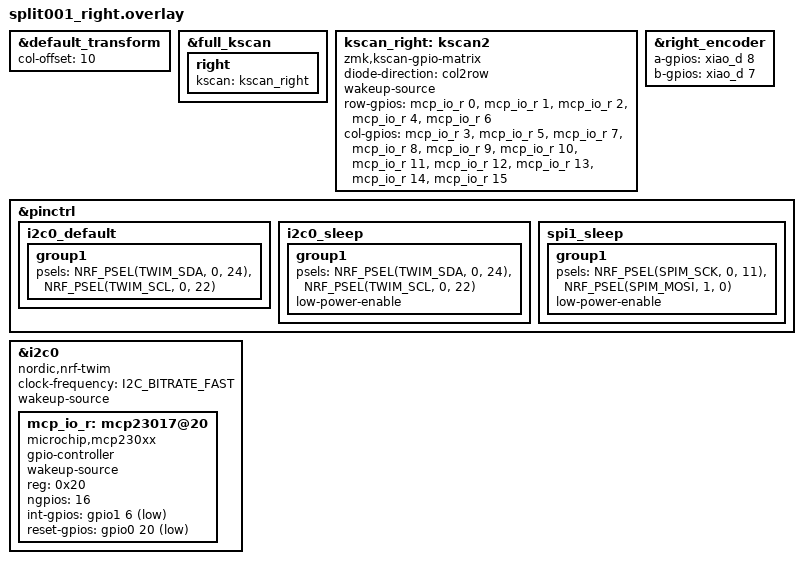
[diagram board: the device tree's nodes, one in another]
#include "split001.dtsi" //Shared between halves

&default_transform {
col-offset = <10>; 
};

&full_kscan {
right {
            kscan = <&kscan_right>;
        };
};

kscan_right: kscan2 {
        compatible = "zmk,kscan-gpio-matrix";
        diode-direction = "col2row";
        status = "okay";
        wakeup-source;

        row-gpios
            =   <&mcp_io_r 0 (GPIO_ACTIVE_HIGH | GPIO_PULL_DOWN)>,
                <&mcp_io_r 1 (GPIO_ACTIVE_HIGH | GPIO_PULL_DOWN)>,
                <&mcp_io_r 2 (GPIO_ACTIVE_HIGH | GPIO_PULL_DOWN)>,
                <&mcp_io_r 4 (GPIO_ACTIVE_HIGH | GPIO_PULL_DOWN)>,
                <&mcp_io_r 6 (GPIO_ACTIVE_HIGH | GPIO_PULL_DOWN)>;

        col-gpios
            =   <&mcp_io_r 3 (GPIO_ACTIVE_HIGH | GPIO_PULL_DOWN)>,
                <&mcp_io_r 5 (GPIO_ACTIVE_HIGH | GPIO_PULL_DOWN)>,
                <&mcp_io_r 7 (GPIO_ACTIVE_HIGH | GPIO_PULL_DOWN)>,
                <&mcp_io_r 8 (GPIO_ACTIVE_HIGH | GPIO_PULL_DOWN)>,
                <&mcp_io_r 9 (GPIO_ACTIVE_HIGH | GPIO_PULL_DOWN)>,
                <&mcp_io_r 10 (GPIO_ACTIVE_HIGH | GPIO_PULL_DOWN)>,
                <&mcp_io_r 11 (GPIO_ACTIVE_HIGH | GPIO_PULL_DOWN)>,
                <&mcp_io_r 12 (GPIO_ACTIVE_HIGH | GPIO_PULL_DOWN)>,
                <&mcp_io_r 13 (GPIO_ACTIVE_HIGH | GPIO_PULL_DOWN)>,
                <&mcp_io_r 14 (GPIO_ACTIVE_HIGH | GPIO_PULL_DOWN)>,
                <&mcp_io_r 15 (GPIO_ACTIVE_HIGH | GPIO_PULL_DOWN)>;
};

&right_encoder{
        status = "okay";
        a-gpios = <&xiao_d 8 (GPIO_ACTIVE_HIGH | GPIO_PULL_UP)>;
        b-gpios = <&xiao_d 7 (GPIO_ACTIVE_HIGH | GPIO_PULL_UP)>;
    };


&pinctrl {

    // I2C for MCP23017
    i2c0_default: i2c0_default {
        group1 {
            psels = <NRF_PSEL(TWIM_SDA, 0, 24)>,
                    <NRF_PSEL(TWIM_SCL, 0, 22)>;
        };
    };
    i2c0_sleep: i2c0_sleep {
        group1 {
            psels = <NRF_PSEL(TWIM_SDA, 0, 24)>,
                    <NRF_PSEL(TWIM_SCL, 0, 22)>;
            low-power-enable;
        };
    };

    
    spi1_sleep: spi1_sleep {
        group1 {
            psels = <NRF_PSEL(SPIM_SCK, 0, 11)>,
                    <NRF_PSEL(SPIM_MOSI, 1, 0)>;
            low-power-enable;
        };
    };
};

&i2c0 {
    compatible = "nordic,nrf-twim";
    status = "okay";
    clock-frequency = <I2C_BITRATE_FAST>;
    wakeup-source;

    mcp_io_r: mcp23017@20 {
        compatible = "microchip,mcp230xx";
        status = "okay";
        gpio-controller;
        wakeup-source;
        reg = <0x20>;
        #gpio-cells = <2>;
        ngpios = <16>;
        int-gpios = <&gpio1 6 (GPIO_PULL_UP | GPIO_ACTIVE_LOW)>;
        reset-gpios = <&gpio0 20 (GPIO_PULL_UP | GPIO_ACTIVE_LOW)>;
    };
};

